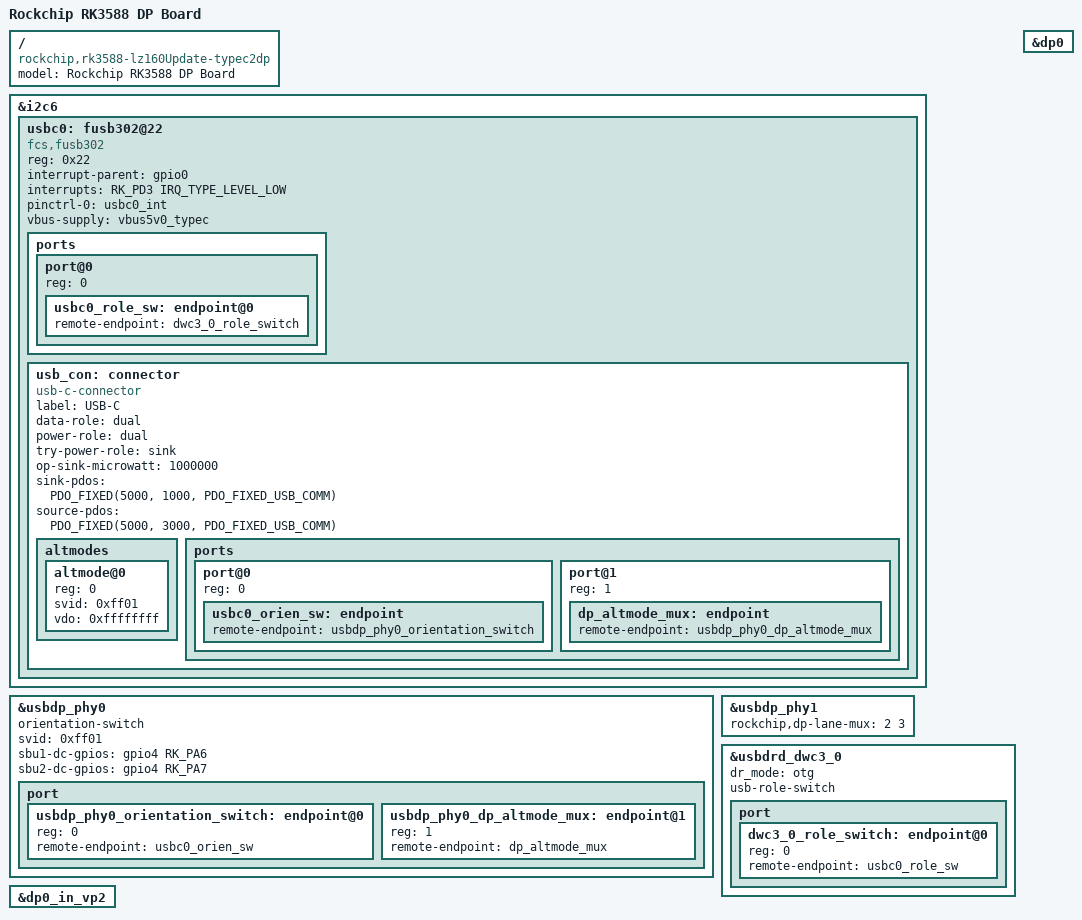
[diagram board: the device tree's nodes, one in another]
// SPDX-License-Identifier: (GPL-2.0+ OR MIT)
/*
 * Copyright (c) 2021 Rockchip Electronics Co., Ltd.
 *
 */
 
 / {
	model = "Rockchip RK3588 DP Board";
	compatible = "rockchip,rk3588-lz160Update-typec2dp", "rockchip,rk3588";
};
 
&i2c6 {
	status = "okay";
	usbc0: fusb302@22 {
		compatible = "fcs,fusb302";
		reg = <0x22>;
		//interrupt-parent = <&gpio3>;
		interrupt-parent = <&gpio0>;
		//interrupts = <RK_PB4 IRQ_TYPE_LEVEL_LOW>;
		interrupts = <RK_PD3 IRQ_TYPE_LEVEL_LOW>;
		pinctrl-names = "default";
		pinctrl-0 = <&usbc0_int>;
		vbus-supply = <&vbus5v0_typec>;
		status = "okay";

		ports {
			#address-cells = <1>;
			#size-cells = <0>;

			port@0 {
				reg = <0>;
				usbc0_role_sw: endpoint@0 {
					remote-endpoint = <&dwc3_0_role_switch>;
				};
			};
		};

		usb_con: connector {
			compatible = "usb-c-connector";
			label = "USB-C";
			data-role = "dual";
			power-role = "dual";
			try-power-role = "sink";
			op-sink-microwatt = <1000000>;
			sink-pdos =
				<PDO_FIXED(5000, 1000, PDO_FIXED_USB_COMM)>;
			source-pdos =
				<PDO_FIXED(5000, 3000, PDO_FIXED_USB_COMM)>;

			altmodes {
				#address-cells = <1>;
				#size-cells = <0>;

				altmode@0 {
					reg = <0>;
					svid = <0xff01>;
					vdo = <0xffffffff>;
				};
			};

			ports {
				#address-cells = <1>;
				#size-cells = <0>;

				port@0 {
					reg = <0>;
					usbc0_orien_sw: endpoint {
						remote-endpoint = <&usbdp_phy0_orientation_switch>;
					};
				};

				port@1 {
					reg = <1>;
					dp_altmode_mux: endpoint {
						remote-endpoint = <&usbdp_phy0_dp_altmode_mux>;
					};
				};
			};
		};
	};
	};

&usbdp_phy0 {
	orientation-switch;
	svid = <0xff01>;
	sbu1-dc-gpios = <&gpio4 RK_PA6 GPIO_ACTIVE_HIGH>;
	sbu2-dc-gpios = <&gpio4 RK_PA7 GPIO_ACTIVE_HIGH>;

	port {
		#address-cells = <1>;
		#size-cells = <0>;
		usbdp_phy0_orientation_switch: endpoint@0 {
			reg = <0>;
			remote-endpoint = <&usbc0_orien_sw>;
		};

		usbdp_phy0_dp_altmode_mux: endpoint@1 {
			reg = <1>;
			remote-endpoint = <&dp_altmode_mux>;
		};
	};
};

&usbdp_phy1 {
	rockchip,dp-lane-mux = <2 3>;
};


&usbdrd_dwc3_0 {
	dr_mode = "otg";
	usb-role-switch;
	port {
		#address-cells = <1>;
		#size-cells = <0>;
		dwc3_0_role_switch: endpoint@0 {
			reg = <0>;
			remote-endpoint = <&usbc0_role_sw>;
		};
	};
};

&dp0 {
	status = "okay";
};

&dp0_in_vp2 {
	status = "okay";
};





